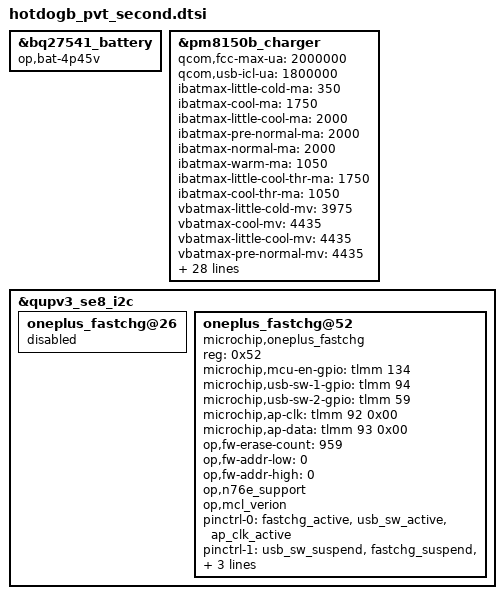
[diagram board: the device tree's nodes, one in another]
/*this is for one project different hw version */
&bq27541_battery {
	op,bat-4p45v;
};

&pm8150b_charger {
	qcom,fcc-max-ua = <2000000>;
	qcom,usb-icl-ua = <1800000>;
	/* ibatmax setting for different temp regions */
	ibatmax-little-cold-ma = <350>;
	ibatmax-cool-ma = <1750>;
	ibatmax-little-cool-ma = <2000>;
	ibatmax-pre-normal-ma = <2000>;
	ibatmax-normal-ma = <2000>;
	ibatmax-warm-ma = <1050>;
	ibatmax-little-cool-thr-ma = <1750>;
	ibatmax-cool-thr-ma = <1050>;
	/* vbatmax setting for different temp regions */
	vbatmax-little-cold-mv = <3975>;
	vbatmax-cool-mv = <4435>;
	vbatmax-little-cool-mv = <4435>;
	vbatmax-pre-normal-mv = <4435>;
	vbatmax-normal-mv = <4435>;
	vbatmax-warm-mv = <4130>;
	little-cool-vbat-thr-mv = <4180>;
	cool-vbat-thr-mv = <4180>;
	/* vbatdet setting for different temp regions */
	vbatdet-little-cold-mv = <3675>;
	vbatdet-cool-mv = <4235>;
	vbatdet-little-cool-mv = <4335>;
	vbatdet-pre-normal-mv = <4335>;
	vbatdet-normal-mv = <4335>;
	vbatdet-warm-mv = <4030>;
	/* temp region settings */
	cold-bat-decidegc = <20>;
	little-cold-bat-decidegc = <0>;
	cool-bat-decidegc = <50>;
	little-cool-bat-decidegc = <120>;
	pre-normal-bat-decidegc = <160>;
	warm-bat-decidegc = <450>;
	hot-bat-decidegc = <500>;
	qcom,otg-cl-ua = <1500000>;
	op,sw-iterm-ma = <210>;
	op,sw-check-full-enable;

	/*ffc temp region*/
	ffc-pre-normal-decidegc = <120>;
	ffc-normal-decidegc = <350>;
	ffc-warm-decidegc = <400>;
	ffc-normal-fcc-ma = <950>;
	ffc-warm-fcc-ma = <1050>;
	ffc-normal-cutoff-ma = <800>;
	ffc-warm-cutoff-ma = <880>;
	ffc-full-vbat-mv = <4480>;

	/delete-property/ qcom,sw-jeita-enable;
};

&qupv3_se8_i2c {
	oneplus_fastchg@26{
		status = "disable";
	};

	oneplus_fastchg@52{
		status = "ok";
		compatible = "microchip,oneplus_fastchg";
		reg = <0x52>;
		microchip,mcu-en-gpio = <&tlmm 134 0x00>;
		microchip,usb-sw-1-gpio = <&tlmm 94 0x00>;
		microchip,usb-sw-2-gpio = <&tlmm 59 0x00>;
		microchip,ap-clk = <&tlmm 92 0x00>;
		microchip,ap-data = <&tlmm 93 0x00>;
		op,fw-erase-count = <959>;
		op,fw-addr-low = <0>;
		op,fw-addr-high = <0>;
		op,n76e_support;
		op,mcl_verion;

		pinctrl-names = "mux_fastchg_active",
		"mux_fastchg_suspend",
		"mcu_data_active",
		"mcu_data_suspend";
		pinctrl-0 = <&fastchg_active
		&usb_sw_active
		&ap_clk_active >;
		pinctrl-1 = <&usb_sw_suspend
		&fastchg_suspend
		&ap_clk_suspend>;
		pinctrl-2 =<&ap_data_active>;
		pinctrl-3 =<&ap_data_suspend>;
	};
};

